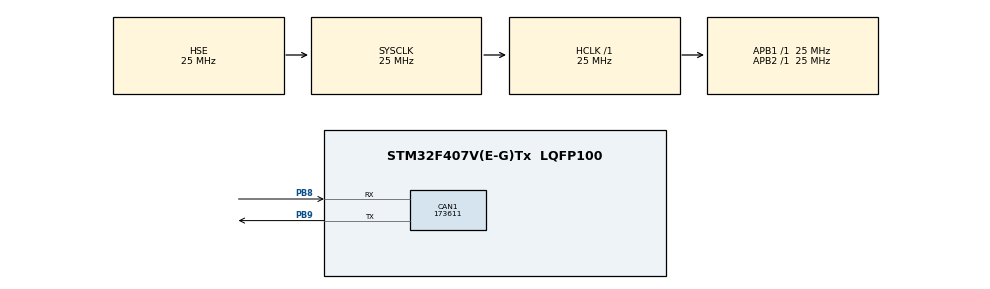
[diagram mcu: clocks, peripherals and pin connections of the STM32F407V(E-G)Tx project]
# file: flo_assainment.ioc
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CAN1.ABOM=ENABLE
CAN1.BS1=CAN_BS1_4TQ
CAN1.BS2=CAN_BS2_4TQ
CAN1.CalculateBaudRate=173611
CAN1.CalculateTimeBit=5760
CAN1.CalculateTimeQuantum=640.0
CAN1.NART=ENABLE
Mcu.Family=STM32F4
Mcu.Name=STM32F407V(E-G)Tx
Mcu.Package=LQFP100
NVIC.CAN1_RX0_IRQn=true\:0\:0\:false\:false\:true\:true\:true\:true
NVIC.CAN1_RX1_IRQn=true\:0\:0\:false\:false\:true\:true\:true\:true
NVIC.CAN1_SCE_IRQn=true\:0\:0\:false\:false\:true\:true\:true\:true
NVIC.CAN1_TX_IRQn=true\:0\:0\:false\:false\:true\:true\:true\:true
NVIC.PriorityGroup=NVIC_PRIORITYGROUP_4
PB8.Mode=CAN_Activate
PB8.Signal=CAN1_RX
PB9.Mode=CAN_Activate
PB9.Signal=CAN1_TX
PC14-OSC32_IN.Mode=LSE-External-Oscillator
PC14-OSC32_IN.Signal=RCC_OSC32_IN
PC15-OSC32_OUT.Mode=LSE-External-Oscillator
PC15-OSC32_OUT.Signal=RCC_OSC32_OUT
PH0-OSC_IN.Mode=HSE-External-Oscillator
PH0-OSC_IN.Signal=RCC_OSC_IN
PH1-OSC_OUT.Mode=HSE-External-Oscillator
PH1-OSC_OUT.Signal=RCC_OSC_OUT
ProjectManager.HeapSize=0x200
ProjectManager.StackSize=0x400
ProjectManager.TargetToolchain=STM32CubeIDE
RCC.48MHZClocksFreq_Value=75000000
RCC.AHBFreq_Value=25000000
RCC.APB1Freq_Value=25000000
RCC.APB1TimFreq_Value=25000000
RCC.APB2Freq_Value=25000000
RCC.APB2TimFreq_Value=25000000
RCC.CortexFreq_Value=25000000
RCC.HCLKFreq_Value=25000000
RCC.HSE_VALUE=25000000
RCC.HSI_VALUE=16000000
RCC.PLLSourceVirtual=RCC_PLLSOURCE_HSE
RCC.SYSCLKFreq_VALUE=25000000
RCC.SYSCLKSource=RCC_SYSCLKSOURCE_HSE
RCC.VCOOutputFreq_Value=300000000
board=custom

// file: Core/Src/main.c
/* USER CODE BEGIN Header */
/**
  ******************************************************************************
  * @file           : main.c
  * @brief          : Main program body
  ******************************************************************************
  * @attention
  *
  * Copyright (c) 2025 STMicroelectronics.
  * All rights reserved.
  *
  * This software is licensed under terms that can be found in the LICENSE file
  * in the root directory of this software component.
  * If no LICENSE file comes with this software, it is provided AS-IS.
  *
  ******************************************************************************
  */
/* USER CODE END Header */
#include "main.h"
#include "can_bms_driver.h"

CAN_HandleTypeDef hcan1;

/* USER CODE BEGIN PV */
CAN_FilterTypeDef Scanfilter;
CAN_TxHeaderTypeDef TxHeader;
CAN_RxHeaderTypeDef RxHeader;
uint32_t  TxMailbox;

extern uint8_t TxData0[8];
extern uint8_t TxData1[8];
uint8_t RxData[8];

/* USER CODE END PV */

void SystemClock_Config(void);
static void MX_GPIO_Init(void);
static void MX_CAN1_Init(void);

int main(void)
{

  /* MCU Configuration--------------------------------------------------------*/

  /* Reset of all peripherals, Initializes the Flash interface and the Systick. */
  HAL_Init();

  /* Configure the system clock */
  SystemClock_Config();

  /* Initialize all configured peripherals */
  MX_GPIO_Init();
  MX_CAN1_Init();
  /* USER CODE BEGIN 2 */
  HAL_CAN_ActivateNotification(&hcan1, TxMailbox);
  /* USER CODE END 2 */

  /* Infinite loop */
  while (1)
  {
	 send_frame0();
 	 HAL_CAN_AddTxMessage(&hcan1, &TxHeader, TxData0, &TxMailbox);
 	 send_frame1();
	 HAL_CAN_AddTxMessage(&hcan1, &TxHeader, TxData1, &TxMailbox);

  }
}

void SystemClock_Config(void)
{
  RCC_OscInitTypeDef RCC_OscInitStruct = {0};
  RCC_ClkInitTypeDef RCC_ClkInitStruct = {0};

  /** Configure the main internal regulator output voltage
  */
  __HAL_RCC_PWR_CLK_ENABLE();
  __HAL_PWR_VOLTAGESCALING_CONFIG(PWR_REGULATOR_VOLTAGE_SCALE1);

  /** Initializes the RCC Oscillators according to the specified parameters
  * in the RCC_OscInitTypeDef structure.
  */
  RCC_OscInitStruct.OscillatorType = RCC_OSCILLATORTYPE_HSE;
  RCC_OscInitStruct.HSEState = RCC_HSE_ON;
  RCC_OscInitStruct.PLL.PLLState = RCC_PLL_NONE;
  if (HAL_RCC_OscConfig(&RCC_OscInitStruct) != HAL_OK)
  {
    Error_Handler();
  }

  /** Initializes the CPU, AHB and APB buses clocks
  */
  RCC_ClkInitStruct.ClockType = RCC_CLOCKTYPE_HCLK|RCC_CLOCKTYPE_SYSCLK
                              |RCC_CLOCKTYPE_PCLK1|RCC_CLOCKTYPE_PCLK2;
  RCC_ClkInitStruct.SYSCLKSource = RCC_SYSCLKSOURCE_HSE;
  RCC_ClkInitStruct.AHBCLKDivider = RCC_SYSCLK_DIV1;
  RCC_ClkInitStruct.APB1CLKDivider = RCC_HCLK_DIV1;
  RCC_ClkInitStruct.APB2CLKDivider = RCC_HCLK_DIV1;

  if (HAL_RCC_ClockConfig(&RCC_ClkInitStruct, FLASH_LATENCY_0) != HAL_OK)
  {
    Error_Handler();
  }
}

static void MX_CAN1_Init(void)
{

  hcan1.Instance = CAN1;
  hcan1.Init.Prescaler = 16;
  hcan1.Init.Mode = CAN_MODE_NORMAL;
  hcan1.Init.SyncJumpWidth = CAN_SJW_1TQ;
  hcan1.Init.TimeSeg1 = CAN_BS1_4TQ;
  hcan1.Init.TimeSeg2 = CAN_BS2_2TQ;
  hcan1.Init.TimeTriggeredMode = DISABLE;
  hcan1.Init.AutoBusOff = ENABLE;
  hcan1.Init.AutoWakeUp = DISABLE;
  hcan1.Init.AutoRetransmission = ENABLE;
  hcan1.Init.ReceiveFifoLocked = DISABLE;
  hcan1.Init.TransmitFifoPriority = DISABLE;
  if (HAL_CAN_Init(&hcan1) != HAL_OK)
  {
    Error_Handler();
  }
  /* USER CODE BEGIN CAN1_Init 2 */
  /*TX CONFIGURATION*/
  TxHeader.IDE                    = CAN_ID_EXT;
  TxHeader.ExtId             	  = 0x00ABCDEF;
  TxHeader.DLC                	  = 8;
  TxHeader.RTR                	  = CAN_RTR_DATA;

 /*FILTER CONFIGURATION*/
  Scanfilter.FilterActivation     = CAN_FILTER_ENABLE;
  Scanfilter.FilterBank           = 0;
  Scanfilter.FilterFIFOAssignment =	CAN_FILTER_FIFO0;
  Scanfilter.FilterIdHigh		  =	0x0000;
  Scanfilter.FilterMaskIdLow      = 0x0000;
  Scanfilter.FilterMode           = CAN_FILTERMODE_IDMASK;
  Scanfilter.FilterScale          = CAN_FILTERSCALE_32BIT;
  Scanfilter.SlaveStartFilterBank = 14;

  /*bms msgs*/

  /*bms msgs end*/

  if(HAL_CAN_ConfigFilter(&hcan1, &Scanfilter) != HAL_OK)
  {
    Error_Handler();
  }

 if( HAL_CAN_Start(&hcan1) != HAL_OK)
 {
	 Error_Handler();
 }
  /* USER CODE END CAN1_Init 2 */

}

static void MX_GPIO_Init(void)
{

  /* GPIO Ports Clock Enable */
  __HAL_RCC_GPIOC_CLK_ENABLE();
  __HAL_RCC_GPIOH_CLK_ENABLE();
  __HAL_RCC_GPIOB_CLK_ENABLE();

}

/* USER CODE BEGIN 4 */
void HAL_CAN_RxFifo0MsgPendingCallback(CAN_HandleTypeDef *hcan)
{
	HAL_CAN_GetRxMessage(&hcan1, CAN_RX_FIFO0, &RxHeader, RxData);
}

/* USER CODE END 4 */

void Error_Handler(void)
{
  __disable_irq();
  while (1)
  {
  }
}
